# RK3399-AP register map
File version: 1
CPU: CA7 r0p1, little endian, MPU, FPU, I-cache, D-cache, VTOR, 4 interrupt priority bits, 32 interrupts
Registers are 32-bit, read-write, reset 0x0 unless marked. A register's access mark holds for its fields unless they carry their own. Offsets are from the block's base; [hi:lo] are bit positions; {n}, {i} and the like mark numbered series; 'fields as' and 'values as' point back to an identical list.

## MAILBOX1
Base 0xFF390000
Same registers: MAILBOX0 0xFF6B0000
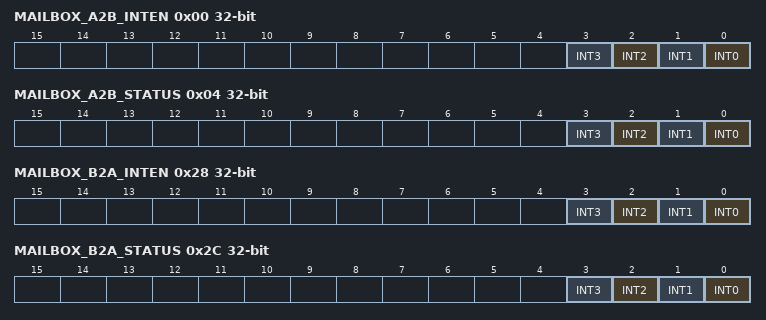
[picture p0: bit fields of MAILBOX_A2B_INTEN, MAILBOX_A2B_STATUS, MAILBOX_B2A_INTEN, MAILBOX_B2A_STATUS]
0x00 MAILBOX_A2B_INTEN — Cortex-A53/Cortex-A72 to Cortex-M0 interrupt enable register/Cortex-A53/Cortex-A72 to MCU interrupt enable register
  [n] INT{n} (n=0..3) — interrupt enable for int{n}
0x04 MAILBOX_A2B_STATUS — Cortex-A53/Cortex-A72 to Cortex-M0 interrupt status register/Cortex-A53/Cortex-A72 to MCU interrupt status register
  [n] INT{n} (n=0..3) — interrupt status for int{n}. when writte 1, int is cleared.
{0x8+8i} MAILBOX_A2B_CMD_{i} (i=0..3) — Cortex-A53/Cortex-A72 to Cortex-M0 command {i}/Cortex-A53/Cortex-A72 to MCU command {i}
  [31:0] COMMAND — command of Cortex-A53/Cortex-A72 to Cortex-M0
{0xC+8i} MAILBOX_A2B_DAT_{i} (i=0..3) — Cortex-A53/Cortex-A72 to Cortex-M0 data {i}/Cortex-A53/Cortex-A72 to MCU data {i}
  [31:0] DATA — data of Cortex-A53/Cortex-A72 to Cortex-M0
0x28 MAILBOX_B2A_INTEN — Cortex-A53/Cortex-A72 to Cortex-M0 interrupt enable register/Cortex-A53/Cortex-A72 to MCU interrupt enable register
  [n] INT{n} (n=0..3) — interrupt enable for int{n}
0x2C MAILBOX_B2A_STATUS — Cortex-M0 to Cortex-A53/Cortex-A72 interrupt status register/MCU to Cortex-A53/Cortex-A72 interrupt status register
  fields as MAILBOX_A2B_STATUS
0x30 MAILBOX_B2A_CMD_0 — Cortex-M0 to Cortex-A53/Cortex-A72 command 0/MCU to Cortex-A53/Cortex-A72 command 0
  [31:0] COMMAND — command of MCU to Cortex-A53/Cortex-A72
0x34 MAILBOX_B2A_DAT_0 — Cortex-M0 to Cortex-A53/Cortex-A72 data 0/MCU to Cortex-A53/Cortex-A72 data 0
  [31:0] DATA — data of MCU to Cortex-A53/Cortex-A72
0x38 MAILBOX_B2A_CMD_1 — Cortex-M0 to Cortex-A53/Cortex-A72 command 1/MCU to Cortex-A53/Cortex-A72 command 1
  [31:0] COMMAND — command of MCU to Cortex-A53/Cortex-A72
0x3C MAILBOX_B2A_DAT_1 — Cortex-M0 to Cortex-A53/Cortex-A72 data 1/MCU to Cortex-A53/Cortex-A72 data 1
  [31:0] DATA — data of MCU to Cortex-A53/Cortex-A72
0x40 MAILBOX_B2A_CMD_2 — Cortex-M0 to Cortex-A53/Cortex-A72 command 2/MCU to Cortex-A53/Cortex-A72 command 2
  [31:0] COMMAND — command of Cortex-M0 to Cortex-A53/Cortex-A72
0x44 MAILBOX_B2A_DAT_2 — Cortex-M0 to Cortex-A53/Cortex-A72 data 2/MCU to Cortex-A53/Cortex-A72 data 2
  [31:0] DATA — data of Cortex-M0 to Cortex-A53/Cortex-A72
0x48 MAILBOX_B2A_CMD_3 — Cortex-M0 to Cortex-A53/Cortex-A72 command 3/MCU to Cortex-A53/Cortex-A72 command 3
  [31:0] COMMAND — command of Cortex-M0 to Cortex-A53/Cortex-A72
0x4C MAILBOX_B2A_DAT_3 — Cortex-M0 to Cortex-A53/Cortex-A72 data 3/MCU to Cortex-A53/Cortex-A72 data 3
  [31:0] DATA — data of Cortex-M0 to Cortex-A53/Cortex-A72
{0x100+4i} MAILBOX_ATOMIC_LOCK_{i:02} (i=0..31) — Lock flag register {i:02}
  [0] ATOMIC_LOCK_{i:02} — lock flag bit {i:02}

## SARADC
Base 0xFF100000
0x00 SARADC_DATA ro — This register contains the data after A/D Conversion.
  [9:0] ADC_DATA — A/D value of the last conversion (DOUT[9:0]).
0x04 SARADC_STAS ro — The status register of A/D Converter.
  [0] ADC_STATUS — ADC status (EOC) 0: ADC stop 1: Conversion in progress
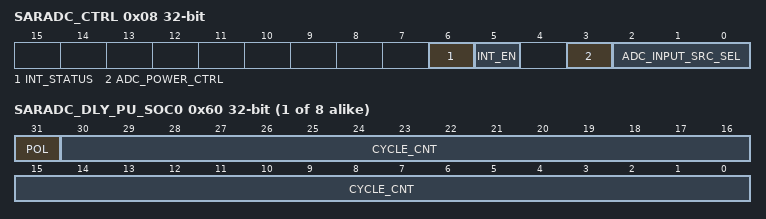
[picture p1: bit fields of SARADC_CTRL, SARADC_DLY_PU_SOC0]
0x08 SARADC_CTRL — The control register of A/D Converter.
  [6] INT_STATUS — Interrupt status. This bit will be set to 1 when end-of-conversion. Set 0 to clear the interrupt.
  [5] INT_EN — Interrupt enable. 0: Disable 1: Enable
  [3] ADC_POWER_CTRL — ADC power down control bit 0: ADC power down; 1: ADC power up and reset. start signal will be asserted (DLY_PU_SOC + 2) sclk clock period later after power up
  [2:0] ADC_INPUT_SRC_SEL — ADC input source selection(CH_SEL[2:0]). 000 : Input source 0 (SARADC_AIN[0]) 001 : Input source 1 (SARADC_AIN[1]) 010 : Input source 2 (SARADC_AIN[2]) 011 : Input source 3 (SARADC_AIN[3]) 100 : Input source 4 (SARADC_AIN[4]) 101 : Input source 5 (SARADC_AIN[5]) Others : Reserved
0x0C SARADC_DLY_PU_SOC — delay between power up and start command
  [5:0] DLY_PU_SOC — delay between power up and start command The start signal will be asserted (DLY_PU_SOC + 2) sclk clock period later after power up
{0x60+4i} SARADC_DLY_PU_SOC{i} access per field (i=0..7) — FIFO Register
  [31] POL rw — Polarity This bit indicates the polarity of the lower 31-bit counter. 0: Low 1: High
  [30:0] CYCLE_CNT ro — High/Low Cycle Counter This 31-bit counter indicates the effective cycles of high/low waveform.
